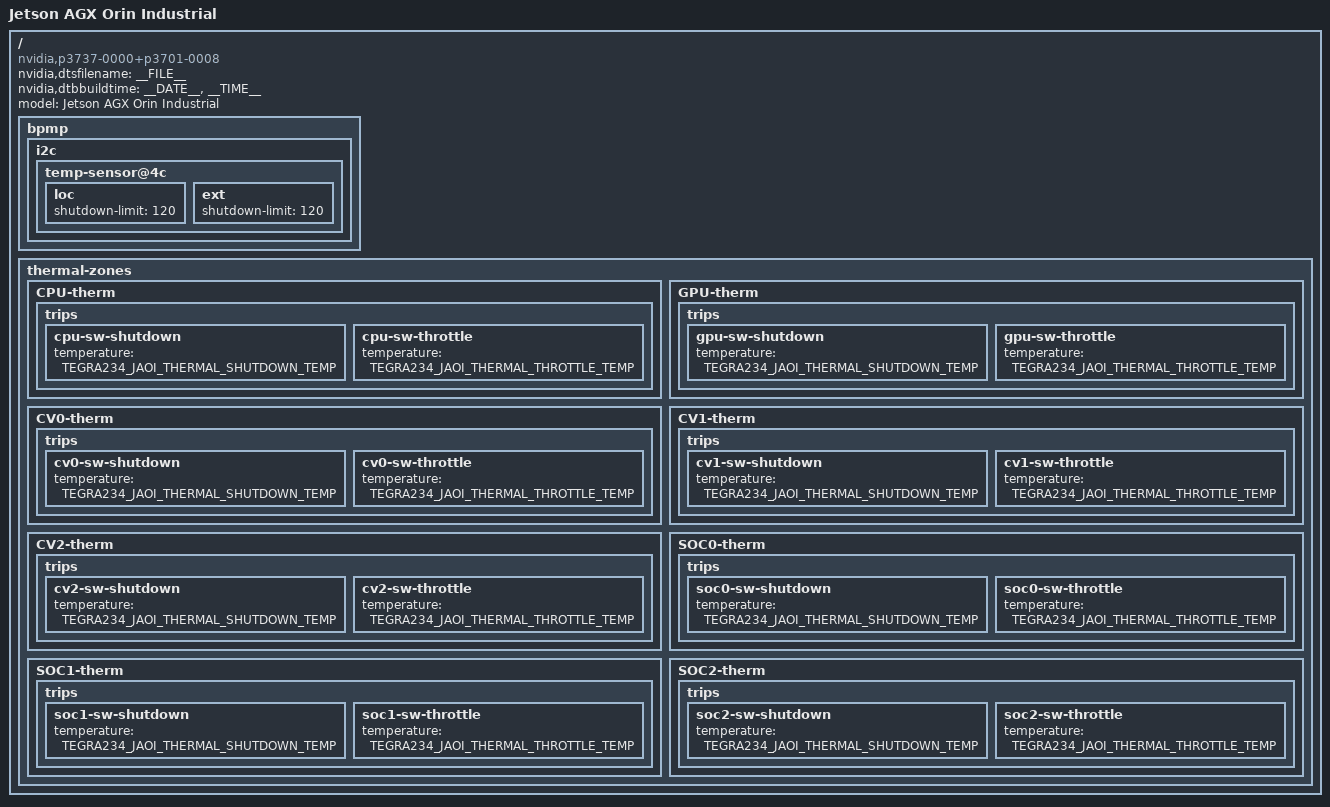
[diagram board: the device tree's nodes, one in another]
/*
 * Top level DTS file for CVM:P3701-0008 and CVB:P3737-0000.
 *
 * Copyright (c) 2023, NVIDIA CORPORATION.  All rights reserved.
 *
 * This program is free software; you can redistribute it and/or modify
 * it under the terms of the GNU General Public License as published by
 * the Free Software Foundation; version 2 of the License.
 *
 * This program is distributed in the hope that it will be useful, but WITHOUT
 * ANY WARRANTY; without even the implied warranty of MERCHANTABILITY or
 * FITNESS FOR A PARTICULAR PURPOSE.  See the GNU General Public License for
 * more details.
 */

/dts-v1/;

#include "tegra234-p3701-0000-p3737-0000.dts"

#define TEGRA234_JAOI_THERMAL_SHUTDOWN_TEMP 117500
#define TEGRA234_JAOI_THERMAL_THROTTLE_TEMP 112000

/ {
	nvidia,dtsfilename = __FILE__;
	nvidia,dtbbuildtime = __DATE__, __TIME__;

	compatible = "nvidia,p3737-0000+p3701-0008", "nvidia,p3701-0008", "nvidia,tegra234", "nvidia,tegra23x";
	model = "Jetson AGX Orin Industrial";

	bpmp {
		i2c {
			temp-sensor@4c {
				loc {
					shutdown-limit = <120>;
				};

				ext {
					shutdown-limit = <120>;
				};
			};
		};
	};

	thermal-zones {
		CPU-therm {
			trips {
				cpu-sw-shutdown {
					temperature = <TEGRA234_JAOI_THERMAL_SHUTDOWN_TEMP>;
				};

				cpu-sw-throttle {
					temperature = <TEGRA234_JAOI_THERMAL_THROTTLE_TEMP>;
				};
			};
		};

		GPU-therm {
			trips {
				gpu-sw-shutdown {
					temperature = <TEGRA234_JAOI_THERMAL_SHUTDOWN_TEMP>;
				};

				gpu-sw-throttle {
					temperature = <TEGRA234_JAOI_THERMAL_THROTTLE_TEMP>;
				};
			};
		};

		CV0-therm {
			trips {
				cv0-sw-shutdown {
					temperature = <TEGRA234_JAOI_THERMAL_SHUTDOWN_TEMP>;
				};

				cv0-sw-throttle {
					temperature = <TEGRA234_JAOI_THERMAL_THROTTLE_TEMP>;
				};
			};
		};

		CV1-therm {
			trips {
				cv1-sw-shutdown {
					temperature = <TEGRA234_JAOI_THERMAL_SHUTDOWN_TEMP>;
				};

				cv1-sw-throttle {
					temperature = <TEGRA234_JAOI_THERMAL_THROTTLE_TEMP>;
				};
			};
		};

		CV2-therm {
			trips {
				cv2-sw-shutdown {
					temperature = <TEGRA234_JAOI_THERMAL_SHUTDOWN_TEMP>;
				};

				cv2-sw-throttle {
					temperature = <TEGRA234_JAOI_THERMAL_THROTTLE_TEMP>;
				};
			};
		};

		SOC0-therm {
			trips {
				soc0-sw-shutdown {
					temperature = <TEGRA234_JAOI_THERMAL_SHUTDOWN_TEMP>;
				};

				soc0-sw-throttle {
					temperature = <TEGRA234_JAOI_THERMAL_THROTTLE_TEMP>;
				};
			};
		};

		SOC1-therm {
			trips {
				soc1-sw-shutdown {
					temperature = <TEGRA234_JAOI_THERMAL_SHUTDOWN_TEMP>;
				};

				soc1-sw-throttle {
					temperature = <TEGRA234_JAOI_THERMAL_THROTTLE_TEMP>;
				};
			};
		};

		SOC2-therm {
			trips {
				soc2-sw-shutdown {
					temperature = <TEGRA234_JAOI_THERMAL_SHUTDOWN_TEMP>;
				};

				soc2-sw-throttle {
					temperature = <TEGRA234_JAOI_THERMAL_THROTTLE_TEMP>;
				};
			};
		};
	};
};
